# uart register map
Vendor: Texas Instruments
Peripheral module from a debugger description file (folder cc32).
Registers are 32-bit, read-write, no defined reset value unless marked. A register's access mark holds for its fields unless they carry their own. Offsets are as the file gives them; lines under a group give offsets from that group; [hi:lo] are bit positions; {n}, {i} and the like mark numbered series; 'fields as' and 'values as' point back to an identical list; <NAME> marks a mode.

## uart
0x00 DR
  [7:0] DATA — Data Transmitted or Received
0x04 RSR_ECR
  [7:0] UART_ECR_DATA — Error Clear
0x18 FR access not given
0x20 ILPR
  [7:0] ILPDVSR — IrDA Low-Power Divisor
0x24 IBRD
  [15:0] DIVINT — Integer Baud-Rate Divisor
0x28 FBRD
  [5:0] DIVFRAC — Fractional Baud-Rate Divisor
0x2C LCRH
  [6:5] WLEN — UART Word Length 0x00000000 : UART_LCRH_WLEN_5 : 5 bits (default) 0x00000020 : UART_LCRH_WLEN_6 : 6 bits 0x00000040 : UART_LCRH_WLEN_7 : 7 bits 0x00000060 : UART_LCRH_WLEN_8 : 8 bits
0x30 CTL access not given
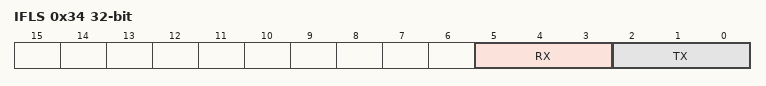
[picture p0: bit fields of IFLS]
0x34 IFLS
  [5:3] RX — UART Receive Interrupt FIFO Level Select
  [2:0] TX — UART Transmit Interrupt FIFO Level Select
0x38 IM access not given
0x3C RIS access not given
0x40 MIS access not given
0x44 ICR access not given
0x48 DMACTL access not given
0x90 LCTL
  [5:4] BLEN — Sync Break Length 0x00000000 : UART_LCTL_BLEN_13T : Sync break length is 13T bits (default) 0x00000010 : UART_LCTL_BLEN_14T : Sync break length is 14T bits 0x00000020 : UART_LCTL_BLEN_15T : Sync break length is 15T bits 0x00000030 : UART_LCTL_BLEN_16T : Sync break length is 16T bits
0x94 LSS
  [15:0] TSS — Timer Snap Shot
0x98 LTIM
  [15:0] TIMER — Timer Value
0xA4 UART_9BITADDR access not given
0xA8 UART_9BITAMASK access not given
0xFC0 PP access not given
0xFC8 CC
  [3:0] CS — UART Baud Clock Source 0x00000005 : UART_CC_CS_PIOSC : PIOSC 0x00000000 : UART_CC_CS_SYSCLK : The system clock (default)
